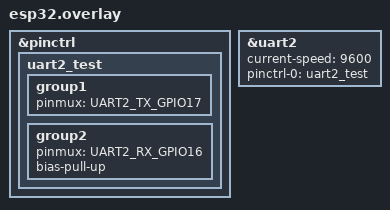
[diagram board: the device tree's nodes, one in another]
&pinctrl {
	uart2_test: uart2_test {
		group1 {
			pinmux = <UART2_TX_GPIO17>;
		};
		group2 {
			pinmux = <UART2_RX_GPIO16>;
			bias-pull-up;
		};
	};
};

dut: &uart2 {
	status = "okay";
	current-speed = <9600>;
	pinctrl-0 = <&uart2_test>;
	pinctrl-names = "default";
};

